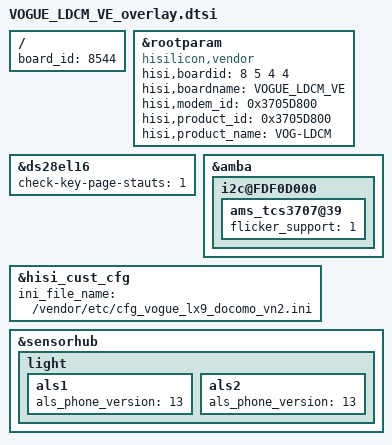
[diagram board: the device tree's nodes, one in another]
/**
 * Copyright (C) 2014 Hisilicon Ltd.
 *
 *  This program is free software; you can redistribute it and/or modify
 *  it under the terms of the GNU General Public License version 2 as
 *  publishhed by the Free Software Foundation.
 */

/include/ "VOGUE_LDCM_VD_overlay.dtsi"

/ {
    board_id = <8544>;
};
    &rootparam{
		compatible = "hisilicon,vendor";
		hisi,boardid = <8 5 4 4>;
		hisi,boardname = "VOGUE_LDCM_VE";
		hisi,modem_id = <0x3705D800>;
		hisi,product_id = <0x3705D800>;
		hisi,product_name = "VOG-LDCM";
	};
	&ds28el16 {
		check-key-page-stauts = <1>;
	};
	&amba {
		i2c@FDF0D000 {
			ams_tcs3707@39 {
				flicker_support = <1>;
			};
		};
	};
	/*hisi customize*/
	&hisi_cust_cfg {
		ini_file_name = "/vendor/etc/cfg_vogue_lx9_docomo_vn2.ini";
	};

	&sensorhub{
		light{
			als1{
				als_phone_version = <13>;
			};
			als2{
				als_phone_version = <13>;
			};
		};
	};
